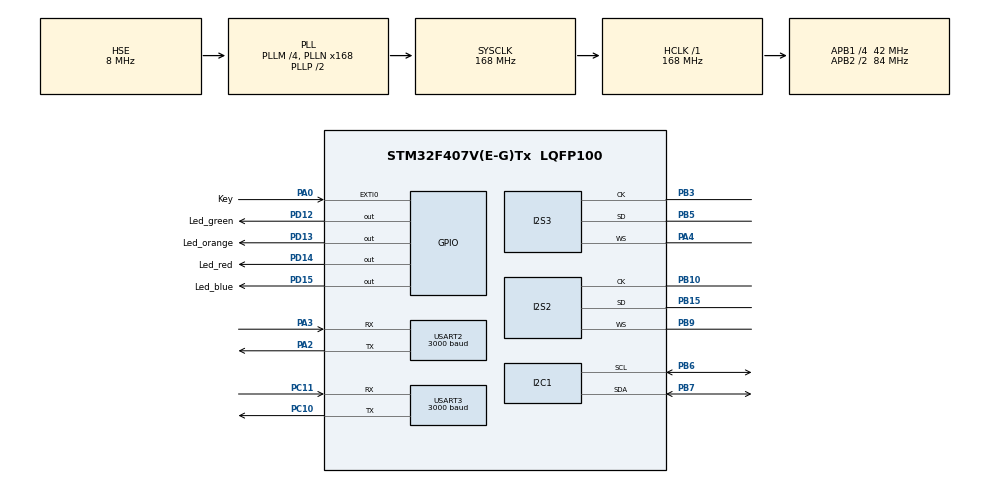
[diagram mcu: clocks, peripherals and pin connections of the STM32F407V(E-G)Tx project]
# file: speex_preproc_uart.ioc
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Dma.Request0=SPI3_RX
Dma.Request1=USART2_TX
Dma.Request2=USART3_RX
Dma.Request3=SPI2_TX
Dma.SPI2_TX.3.Direction=DMA_MEMORY_TO_PERIPH
Dma.SPI2_TX.3.FIFOMode=DMA_FIFOMODE_ENABLE
Dma.SPI2_TX.3.FIFOThreshold=DMA_FIFO_THRESHOLD_HALFFULL
Dma.SPI2_TX.3.Instance=DMA1_Stream4
Dma.SPI2_TX.3.MemBurst=DMA_MBURST_SINGLE
Dma.SPI2_TX.3.MemDataAlignment=DMA_MDATAALIGN_HALFWORD
Dma.SPI2_TX.3.MemInc=DMA_MINC_ENABLE
Dma.SPI2_TX.3.Mode=DMA_CIRCULAR
Dma.SPI2_TX.3.PeriphBurst=DMA_PBURST_SINGLE
Dma.SPI2_TX.3.PeriphDataAlignment=DMA_PDATAALIGN_HALFWORD
Dma.SPI2_TX.3.PeriphInc=DMA_PINC_DISABLE
Dma.SPI2_TX.3.Priority=DMA_PRIORITY_HIGH
Dma.SPI3_RX.0.Direction=DMA_PERIPH_TO_MEMORY
Dma.SPI3_RX.0.FIFOMode=DMA_FIFOMODE_ENABLE
Dma.SPI3_RX.0.FIFOThreshold=DMA_FIFO_THRESHOLD_HALFFULL
Dma.SPI3_RX.0.Instance=DMA1_Stream0
Dma.SPI3_RX.0.MemBurst=DMA_MBURST_SINGLE
Dma.SPI3_RX.0.MemDataAlignment=DMA_MDATAALIGN_HALFWORD
Dma.SPI3_RX.0.MemInc=DMA_MINC_ENABLE
Dma.SPI3_RX.0.Mode=DMA_CIRCULAR
Dma.SPI3_RX.0.PeriphBurst=DMA_PBURST_SINGLE
Dma.SPI3_RX.0.PeriphDataAlignment=DMA_PDATAALIGN_HALFWORD
Dma.SPI3_RX.0.PeriphInc=DMA_PINC_DISABLE
Dma.SPI3_RX.0.Priority=DMA_PRIORITY_VERY_HIGH
Dma.USART2_TX.1.Direction=DMA_MEMORY_TO_PERIPH
Dma.USART2_TX.1.FIFOMode=DMA_FIFOMODE_DISABLE
Dma.USART2_TX.1.Instance=DMA1_Stream6
Dma.USART2_TX.1.MemDataAlignment=DMA_MDATAALIGN_BYTE
Dma.USART2_TX.1.MemInc=DMA_MINC_ENABLE
Dma.USART2_TX.1.Mode=DMA_NORMAL
Dma.USART2_TX.1.PeriphDataAlignment=DMA_PDATAALIGN_BYTE
Dma.USART2_TX.1.PeriphInc=DMA_PINC_DISABLE
Dma.USART2_TX.1.Priority=DMA_PRIORITY_LOW
Dma.USART3_RX.2.Direction=DMA_PERIPH_TO_MEMORY
Dma.USART3_RX.2.FIFOMode=DMA_FIFOMODE_DISABLE
Dma.USART3_RX.2.Instance=DMA1_Stream1
Dma.USART3_RX.2.MemDataAlignment=DMA_MDATAALIGN_BYTE
Dma.USART3_RX.2.MemInc=DMA_MINC_ENABLE
Dma.USART3_RX.2.Mode=DMA_CIRCULAR
Dma.USART3_RX.2.PeriphDataAlignment=DMA_PDATAALIGN_BYTE
Dma.USART3_RX.2.PeriphInc=DMA_PINC_DISABLE
Dma.USART3_RX.2.Priority=DMA_PRIORITY_LOW
I2S2.AudioFreq=I2S_AUDIOFREQ_8K
I2S2.ErrorAudioFreq=0.15 %
I2S2.FullDuplexMode=I2S_FULLDUPLEXMODE_DISABLE
I2S2.Instance=SPI$Index
I2S2.RealAudioFreq=8.012 KHz
I2S2.VirtualMode=I2S_MODE_MASTER
I2S3.AudioFreq=I2S_AUDIOFREQ_8K
I2S3.ErrorAudioFreq=0.15 %
I2S3.FullDuplexMode=I2S_FULLDUPLEXMODE_DISABLE
I2S3.Instance=SPI$Index
I2S3.Mode=I2S_MODE_MASTER_RX
I2S3.RealAudioFreq=8.012 KHz
I2S3.VirtualMode=I2S_MODE_MASTER
Mcu.Family=STM32F4
Mcu.Name=STM32F407V(E-G)Tx
Mcu.Package=LQFP100
NVIC.DMA1_Stream0_IRQn=true\:0\:0\:false\:false\:true\:false
NVIC.DMA1_Stream1_IRQn=true\:0\:0\:false\:false\:true\:false
NVIC.DMA1_Stream4_IRQn=true\:0\:0\:false\:false\:true\:false
NVIC.DMA1_Stream6_IRQn=true\:0\:0\:false\:false\:true\:false
NVIC.EXTI0_IRQn=true\:0\:0\:false\:false\:true\:true
NVIC.PriorityGroup=NVIC_PRIORITYGROUP_4
NVIC.USART2_IRQn=true\:0\:0\:false\:false\:true\:true
NVIC.USART3_IRQn=true\:0\:0\:false\:false\:true\:true
PA0-WKUP.GPIO_Label=Key
PA0-WKUP.GPIO_ModeDefaultEXTI=GPIO_MODE_IT_RISING
PA0-WKUP.GPIO_PuPd=GPIO_PULLDOWN
PA0-WKUP.Signal=GPXTI0
PA13.Mode=Serial_Wire
PA13.Signal=SYS_JTMS-SWDIO
PA14.Mode=Serial_Wire
PA14.Signal=SYS_JTCK-SWCLK
PA2.Mode=Asynchronous
PA2.Signal=USART2_TX
PA3.Mode=Asynchronous
PA3.Signal=USART2_RX
PA4.Mode=Half_Duplex_Master
PA4.Signal=I2S3_WS
PB10.Mode=Half_Duplex_Master
PB10.Signal=I2S2_CK
PB15.Mode=Half_Duplex_Master
PB15.Signal=I2S2_SD
PB3.Mode=Half_Duplex_Master
PB3.Signal=I2S3_CK
PB5.Mode=Half_Duplex_Master
PB5.Signal=I2S3_SD
PB6.Mode=I2C
PB6.Signal=I2C1_SCL
PB7.Mode=I2C
PB7.Signal=I2C1_SDA
PB9.Mode=Half_Duplex_Master
PB9.Signal=I2S2_WS
PC10.Mode=Asynchronous
PC10.Signal=USART3_TX
PC11.Mode=Asynchronous
PC11.Signal=USART3_RX
PD12.GPIO_Label=Led_green
PD12.Signal=GPIO_Output
PD13.GPIO_Label=Led_orange
PD13.Signal=GPIO_Output
PD14.GPIO_Label=Led_red
PD14.Signal=GPIO_Output
PD15.GPIO_Label=Led_blue
PD15.Signal=GPIO_Output
PH0-OSC_IN.Mode=HSE-External-Oscillator
PH0-OSC_IN.Signal=RCC_OSC_IN
PH1-OSC_OUT.Mode=HSE-External-Oscillator
PH1-OSC_OUT.Signal=RCC_OSC_OUT
ProjectManager.HeapSize=0x10000
ProjectManager.StackSize=0x4000
ProjectManager.TargetToolchain=MDK-ARM V5
RCC.48MHZClocksFreq_Value=84000000
RCC.AHBFreq_Value=168000000
RCC.APB1CLKDivider=RCC_HCLK_DIV4
RCC.APB1Freq_Value=42000000
RCC.APB1TimFreq_Value=84000000
RCC.APB2CLKDivider=RCC_HCLK_DIV2
RCC.APB2Freq_Value=84000000
RCC.APB2TimFreq_Value=168000000
RCC.CortexFreq_Value=168000000
RCC.HCLKFreq_Value=168000000
RCC.HSE_VALUE=8000000
RCC.HSI_VALUE=16000000
RCC.LSE_VALUE=32768
RCC.PLLI2SN=50
RCC.PLLM=4
RCC.PLLN=168
RCC.PLLSourceVirtual=RCC_PLLSOURCE_HSE
RCC.SYSCLKFreq_VALUE=168000000
RCC.SYSCLKSource=RCC_SYSCLKSOURCE_PLLCLK
RCC.VCOOutputFreq_Value=336000000
USART2.BaudRate=3000
USART2.Mode=MODE_TX
USART2.VirtualMode=VM_ASYNC
USART3.BaudRate=3000
USART3.Mode=MODE_RX
USART3.VirtualMode=VM_ASYNC
board=custom

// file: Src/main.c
/**
  ******************************************************************************
  * @file           : main.c
  * @brief          : Main program body
  ******************************************************************************
  ** This notice applies to any and all portions of this file
  * that are not between comment pairs USER CODE BEGIN and
  * USER CODE END. Other portions of this file, whether
  * inserted by the user or by software development tools
  * are owned by their respective copyright owners.
  *
  * COPYRIGHT(c) 2018 STMicroelectronics
  *
  * Redistribution and use in source and binary forms, with or without modification,
  * are permitted provided that the following conditions are met:
  *   1. Redistributions of source code must retain the above copyright notice,
  *      this list of conditions and the following disclaimer.
  *   2. Redistributions in binary form must reproduce the above copyright notice,
  *      this list of conditions and the following disclaimer in the documentation
  *      and/or other materials provided with the distribution.
  *   3. Neither the name of STMicroelectronics nor the names of its contributors
  *      may be used to endorse or promote products derived from this software
  *      without specific prior written permission.
  *
  * THIS SOFTWARE IS PROVIDED BY THE COPYRIGHT HOLDERS AND CONTRIBUTORS "AS IS"
  * AND ANY EXPRESS OR IMPLIED WARRANTIES, INCLUDING, BUT NOT LIMITED TO, THE
  * IMPLIED WARRANTIES OF MERCHANTABILITY AND FITNESS FOR A PARTICULAR PURPOSE ARE
  * DISCLAIMED. IN NO EVENT SHALL THE COPYRIGHT HOLDER OR CONTRIBUTORS BE LIABLE
  * FOR ANY DIRECT, INDIRECT, INCIDENTAL, SPECIAL, EXEMPLARY, OR CONSEQUENTIAL
  * DAMAGES (INCLUDING, BUT NOT LIMITED TO, PROCUREMENT OF SUBSTITUTE GOODS OR
  * SERVICES; LOSS OF USE, DATA, OR PROFITS; OR BUSINESS INTERRUPTION) HOWEVER
  * CAUSED AND ON ANY THEORY OF LIABILITY, WHETHER IN CONTRACT, STRICT LIABILITY,
  * OR TORT (INCLUDING NEGLIGENCE OR OTHERWISE) ARISING IN ANY WAY OUT OF THE USE
  * OF THIS SOFTWARE, EVEN IF ADVISED OF THE POSSIBILITY OF SUCH DAMAGE.
  *
  ******************************************************************************
  */
#include "main.h"
#include "stm32f4xx_hal.h"
#include "dma.h"
#include "i2c.h"
#include "i2s.h"
#include "usart.h"
#include "gpio.h"

/* USER CODE BEGIN Includes */
#include "programm_vocoder.h"

/* USER CODE END Includes */

/* USER CODE BEGIN PV */
/* Private variables ---------------------------------------------------------*/

/* USER CODE END PV */

void SystemClock_Config(void);

/* USER CODE BEGIN PFP */
/* Private function prototypes -----------------------------------------------*/

/* USER CODE END PFP */

int main(void)
{

  /* MCU Configuration----------------------------------------------------------*/

  /* Reset of all peripherals, Initializes the Flash interface and the Systick. */
  HAL_Init();

  /* Configure the system clock */
  SystemClock_Config();

  /* Initialize all configured peripherals */
  MX_GPIO_Init();
  MX_DMA_Init();
  MX_I2C1_Init();
  MX_I2S2_Init();
  MX_I2S3_Init();
  MX_USART2_UART_Init();
  MX_USART3_UART_Init();
  /* USER CODE BEGIN 2 */
  start_init();
  /* USER CODE END 2 */

  /* Infinite loop */
  /* USER CODE BEGIN WHILE */
  while (1)
  {
      run_vocoder();

  /* USER CODE END WHILE */

  }

}

void SystemClock_Config(void)
{

  RCC_OscInitTypeDef RCC_OscInitStruct;
  RCC_ClkInitTypeDef RCC_ClkInitStruct;
  RCC_PeriphCLKInitTypeDef PeriphClkInitStruct;

    /**Configure the main internal regulator output voltage
    */
  __HAL_RCC_PWR_CLK_ENABLE();

  __HAL_PWR_VOLTAGESCALING_CONFIG(PWR_REGULATOR_VOLTAGE_SCALE1);

    /**Initializes the CPU, AHB and APB busses clocks
    */
  RCC_OscInitStruct.OscillatorType = RCC_OSCILLATORTYPE_HSE;
  RCC_OscInitStruct.HSEState = RCC_HSE_ON;
  RCC_OscInitStruct.PLL.PLLState = RCC_PLL_ON;
  RCC_OscInitStruct.PLL.PLLSource = RCC_PLLSOURCE_HSE;
  RCC_OscInitStruct.PLL.PLLM = 4;
  RCC_OscInitStruct.PLL.PLLN = 168;
  RCC_OscInitStruct.PLL.PLLP = RCC_PLLP_DIV2;
  RCC_OscInitStruct.PLL.PLLQ = 4;
  if (HAL_RCC_OscConfig(&RCC_OscInitStruct) != HAL_OK)
  {
    _Error_Handler(__FILE__, __LINE__);
  }

    /**Initializes the CPU, AHB and APB busses clocks
    */
  RCC_ClkInitStruct.ClockType = RCC_CLOCKTYPE_HCLK|RCC_CLOCKTYPE_SYSCLK
                              |RCC_CLOCKTYPE_PCLK1|RCC_CLOCKTYPE_PCLK2;
  RCC_ClkInitStruct.SYSCLKSource = RCC_SYSCLKSOURCE_PLLCLK;
  RCC_ClkInitStruct.AHBCLKDivider = RCC_SYSCLK_DIV1;
  RCC_ClkInitStruct.APB1CLKDivider = RCC_HCLK_DIV4;
  RCC_ClkInitStruct.APB2CLKDivider = RCC_HCLK_DIV2;

  if (HAL_RCC_ClockConfig(&RCC_ClkInitStruct, FLASH_LATENCY_5) != HAL_OK)
  {
    _Error_Handler(__FILE__, __LINE__);
  }

  PeriphClkInitStruct.PeriphClockSelection = RCC_PERIPHCLK_I2S;
  PeriphClkInitStruct.PLLI2S.PLLI2SN = 50;
  PeriphClkInitStruct.PLLI2S.PLLI2SR = 2;
  if (HAL_RCCEx_PeriphCLKConfig(&PeriphClkInitStruct) != HAL_OK)
  {
    _Error_Handler(__FILE__, __LINE__);
  }

    /**Configure the Systick interrupt time
    */
  HAL_SYSTICK_Config(HAL_RCC_GetHCLKFreq()/1000);

    /**Configure the Systick
    */
  HAL_SYSTICK_CLKSourceConfig(SYSTICK_CLKSOURCE_HCLK);

  /* SysTick_IRQn interrupt configuration */
  HAL_NVIC_SetPriority(SysTick_IRQn, 0, 0);
}

void _Error_Handler(char *file, int line)
{
  while(1)
  {
  }
}

/************************ (C) COPYRIGHT STMicroelectronics *****END OF FILE****/
